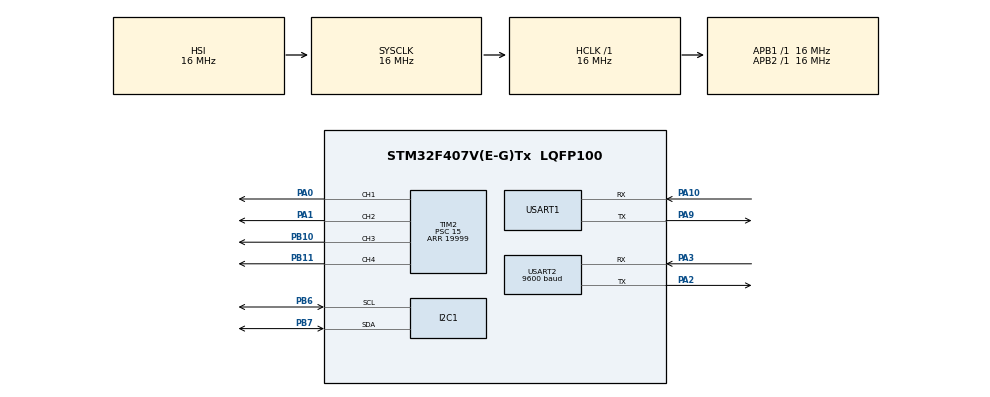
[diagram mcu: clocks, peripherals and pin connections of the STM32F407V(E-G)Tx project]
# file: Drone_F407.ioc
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Mcu.Family=STM32F4
Mcu.Name=STM32F407V(E-G)Tx
Mcu.Package=LQFP100
NVIC.PriorityGroup=NVIC_PRIORITYGROUP_4
PA0-WKUP.Signal=S_TIM2_CH1_ETR
PA1.Signal=S_TIM2_CH2
PA10.Mode=Asynchronous
PA10.Signal=USART1_RX
PA13.Mode=Serial_Wire
PA13.Signal=SYS_JTMS-SWDIO
PA14.Mode=Serial_Wire
PA14.Signal=SYS_JTCK-SWCLK
PA2.Mode=Asynchronous
PA2.Signal=USART2_TX
PA3.Mode=Asynchronous
PA3.Signal=USART2_RX
PA9.Mode=Asynchronous
PA9.Signal=USART1_TX
PB10.Signal=S_TIM2_CH3
PB11.Signal=S_TIM2_CH4
PB6.Mode=I2C
PB6.Signal=I2C1_SCL
PB7.Mode=I2C
PB7.Signal=I2C1_SDA
ProjectManager.HeapSize=0x200
ProjectManager.StackSize=0x400
ProjectManager.TargetToolchain=Makefile
RCC.AHBFreq_Value=16000000
RCC.APB1Freq_Value=16000000
RCC.APB2Freq_Value=16000000
RCC.CortexFreq_Value=16000000
RCC.HSE_VALUE=25000000
RCC.HSI_VALUE=16000000
RCC.LSE_VALUE=32768
RCC.SYSCLKFreq_VALUE=16000000
RCC.VCOOutputFreq_Value=192000000
SH.S_TIM2_CH1_ETR.0=TIM2_CH1,PWM Generation1 CH1
SH.S_TIM2_CH2.0=TIM2_CH2,PWM Generation2 CH2
SH.S_TIM2_CH3.0=TIM2_CH3,PWM Generation3 CH3
SH.S_TIM2_CH4.0=TIM2_CH4,PWM Generation4 CH4
TIM2.Channel-PWM\ Generation1\ CH1=TIM_CHANNEL_1
TIM2.Channel-PWM\ Generation2\ CH2=TIM_CHANNEL_2
TIM2.Channel-PWM\ Generation3\ CH3=TIM_CHANNEL_3
TIM2.Channel-PWM\ Generation4\ CH4=TIM_CHANNEL_4
TIM2.Period=19999
TIM2.Prescaler=15
TIM2.Pulse-PWM\ Generation1\ CH1=1000
USART1.VirtualMode=VM_ASYNC
USART2.BaudRate=9600
USART2.VirtualMode=VM_ASYNC
VP_TIM2_VS_ClockSourceINT.Mode=Internal
board=custom

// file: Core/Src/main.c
/* USER CODE BEGIN Header */
/**
  ******************************************************************************
  * @file           : main.c
  * @brief          : Main program body
  ******************************************************************************
  * @attention
  *
  * Copyright (c) 2026 STMicroelectronics.
  * All rights reserved.
  *
  * This software is licensed under terms that can be found in the LICENSE file
  * in the root directory of this software component.
  * If no LICENSE file comes with this software, it is provided AS-IS.
  *
  ******************************************************************************
  */
/* USER CODE END Header */
#include "main.h"
#include "i2c.h"
#include "tim.h"
#include "usart.h"
#include "gpio.h"

/* USER CODE BEGIN Includes */
#include "app_main.hpp"
/* USER CODE END Includes */

void SystemClock_Config(void);

int main(void)
{

  /* MCU Configuration--------------------------------------------------------*/

  /* Reset of all peripherals, Initializes the Flash interface and the Systick. */
  HAL_Init();

  /* Configure the system clock */
  SystemClock_Config();

  /* Initialize all configured peripherals */
  MX_GPIO_Init();
  MX_I2C1_Init();
  MX_USART1_UART_Init();
  MX_USART2_UART_Init();
  MX_TIM2_Init();
  /* USER CODE BEGIN 2 */
  App_Init();

  /* USER CODE END 2 */

  /* Infinite loop */
  /* USER CODE BEGIN WHILE */
  while (1)
  {
    App_Loop();

    /* USER CODE END WHILE */

  }
}

void SystemClock_Config(void)
{
  RCC_OscInitTypeDef RCC_OscInitStruct = {0};
  RCC_ClkInitTypeDef RCC_ClkInitStruct = {0};

  /** Configure the main internal regulator output voltage
  */
  __HAL_RCC_PWR_CLK_ENABLE();
  __HAL_PWR_VOLTAGESCALING_CONFIG(PWR_REGULATOR_VOLTAGE_SCALE1);

  /** Initializes the RCC Oscillators according to the specified parameters
  * in the RCC_OscInitTypeDef structure.
  */
  RCC_OscInitStruct.OscillatorType = RCC_OSCILLATORTYPE_HSI;
  RCC_OscInitStruct.HSIState = RCC_HSI_ON;
  RCC_OscInitStruct.HSICalibrationValue = RCC_HSICALIBRATION_DEFAULT;
  RCC_OscInitStruct.PLL.PLLState = RCC_PLL_NONE;
  if (HAL_RCC_OscConfig(&RCC_OscInitStruct) != HAL_OK)
  {
    Error_Handler();
  }

  /** Initializes the CPU, AHB and APB buses clocks
  */
  RCC_ClkInitStruct.ClockType = RCC_CLOCKTYPE_HCLK|RCC_CLOCKTYPE_SYSCLK
                              |RCC_CLOCKTYPE_PCLK1|RCC_CLOCKTYPE_PCLK2;
  RCC_ClkInitStruct.SYSCLKSource = RCC_SYSCLKSOURCE_HSI;
  RCC_ClkInitStruct.AHBCLKDivider = RCC_SYSCLK_DIV1;
  RCC_ClkInitStruct.APB1CLKDivider = RCC_HCLK_DIV1;
  RCC_ClkInitStruct.APB2CLKDivider = RCC_HCLK_DIV1;

  if (HAL_RCC_ClockConfig(&RCC_ClkInitStruct, FLASH_LATENCY_0) != HAL_OK)
  {
    Error_Handler();
  }
}

/* USER CODE BEGIN 4 */
#ifdef __GNUC__
#define PUTCHAR_PROTOTYPE int __io_putchar(int ch)
#else
  #define PUTCHAR_PROTOTYPE int fputc(int ch, FILE *f)
#endif /* __GNUC__ */
PUTCHAR_PROTOTYPE
{
  HAL_UART_Transmit(&huart1, (uint8_t *)&ch, 1, 0xFFFF);
  return ch;
}

/* USER CODE END 4 */

void Error_Handler(void)
{
  __disable_irq();
  while (1)
  {
  }
}
